# CH32V205 register map
Vendor: WCH Ltd.; File version: 1.0
Registers are 32-bit, read-write, reset 0x0 unless marked. A register's access mark holds for its fields unless they carry their own. Offsets are from the block's base; [hi:lo] are bit positions.

## QSPI1
Base 0x40024C00
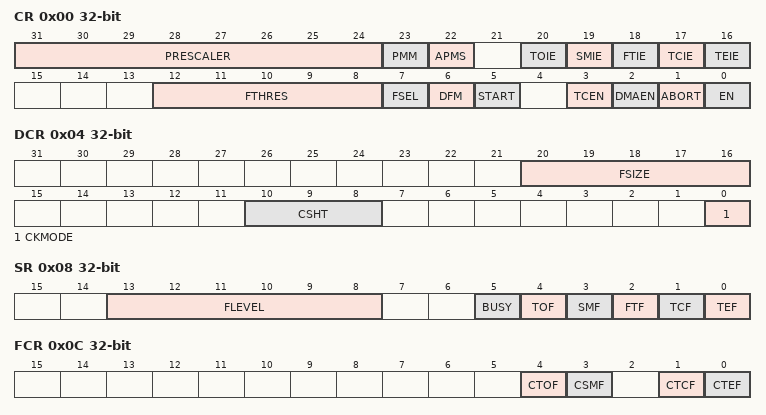
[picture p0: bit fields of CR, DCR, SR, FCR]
0x00 CR access per field — QSPI control register
  [31:24] PRESCALER rw — clock prescaler
  [23] PMM rw — Polling match mode
  [22] APMS rw — Automatic poll mode stop
  [20] TOIE rw — TimeOut interrupt enable This bit enables the TimeOut interrupt.
  [19] SMIE rw — Status match interrupt enable This bit enables the status match interrupt.
  [18] FTIE rw — FIFO threshold interrupt enable This bit enables the FIFO threshold interrupt.
  [17] TCIE rw — Transfer complete interrupt enable This bit enables the transfer complete interrupt.
  [16] TEIE rw — Transfer error interrupt enable This bit enables the transfer error interrupt.
  [12:8] FTHRES rw — FIFO threshold level Defines
  [7] FSEL rw — Flash memory selection
  [6] DFM rw — Dual-flash mode This bit activates dual-flash mode
  [5] START wo — start the FLASH command sequence
  [3] TCEN rw — Timeout counter enable
  [2] DMAEN rw — DMA mode enabled
  [1] ABORT rw — Abort request This bit aborts the on-going command sequence
  [0] EN rw — Enable Enable the QSPI
0x04 DCR — QSPI device configuration register
  [20:16] FSIZE — Flash memory size
  [10:8] CSHT — Chip select high time
  [0] CKMODE — indicates the level that clk takes between command
0x08 SR ro — QSPI status register
  [13:8] FLEVEL — FIFO level
  [5] BUSY — Busy This bit is set when an operation is on going
  [4] TOF — Timeout flag This bit is set when timeout occurs
  [3] SMF — Status match flag
  [2] FTF — FIFO threshold flag
  [1] TCF — Transfer complete flag
  [0] TEF — Transfer error flag
0x0C FCR — QSPI flag clear register
  [4] CTOF — Clear timeout flag Writing 1 clears the TOF flag in the QSPI_SR register
  [3] CSMF — Clear status match flag Writing 1 clears the SMF flag in the QSPI_SR register
  [1] CTCF — Clear transfer complete flag Writing 1 clears the TCF flag in the QSPI_SR register
  [0] CTEF — Clear transfer error flag Writing 1 clears the TEF flag in the QSPI_SR register
0x10 DLR — QSPI data length register
  [31:0] DL — Data length
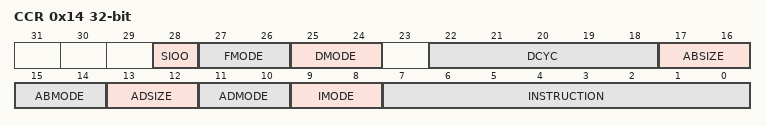
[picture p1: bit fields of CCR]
0x14 CCR — QSPI communication configuration register
  [28] SIOO — Send instruction only once mode
  [27:26] FMODE — Functional mode
  [25:24] DMODE — Data mode
  [22:18] DCYC — Number of dummy cycles
  [17:16] ABSIZE — Alternate bytes size
  [15:14] ABMODE — Alternate bytes mode
  [13:12] ADSIZE — Address size
  [11:10] ADMODE — Address mode
  [9:8] IMODE — Instruction mode
  [7:0] INSTRUCTION
0x18 AR — QSPI address register
  [31:0] ADDRESS — QSPI Address
0x1C ABR — QSPI alternate bytes registers
  [31:0] ALTERNATE — Alternate Bytes Optional data to be send to the external SPI device right after the address.
0x20 DR — QSPI data register
  [31:0] DATA
0x24 PSMKR — QSPI polling status mask register
  [31:0] MASK — Status mask Mask to be applied to the status bytes received in polling mode
0x28 PSMAR — QSPI polling status match register
  [31:0] MATCH — Status match Value to be compared with the masked status register to get a match. This field can be written only when BUSY = 0.
0x2C PIR — QSPI polling interval register
  [15:0] INTERVAL — Polling interval Number of CLK cycles between to read during automatic polling phases. This field can be written only when BUSY = 0.
0x30 LPTR — QSPI low-power timeout register
  [15:0] TIMEOUT

## FSMC — Flexible static memory controller
Base 0xA0000000
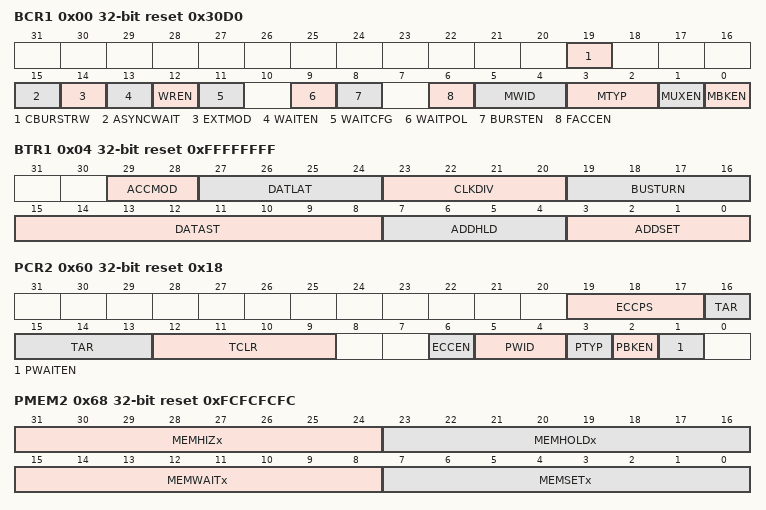
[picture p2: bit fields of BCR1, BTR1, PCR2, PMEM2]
0x00 BCR1 reset 0x30D0 — SRAM/NOR-Flash chip-select control register 1
  [19] CBURSTRW — Write burst enable
  [15] ASYNCWAIT — Wait signal during asynchronous transfers
  [14] EXTMOD — Extended mode enable
  [13] WAITEN — Wait enable bit
  [12] WREN — Write enable bit
  [11] WAITCFG — Wait timing configuration
  [9] WAITPOL — Wait signal polarity bit
  [8] BURSTEN — Burst enable bit
  [6] FACCEN — Flash access enable
  [5:4] MWID — Memory databus width
  [3:2] MTYP — Memory type
  [1] MUXEN — Address/data multiplexing enable bit
  [0] MBKEN — Memory bank enable bit
0x04 BTR1 reset 0xFFFFFFFF — SRAM/NOR-Flash chip-select timing register 1
  [29:28] ACCMOD — Access mode
  [27:24] DATLAT — Data latency for synchronous NOR Flash memory
  [23:20] CLKDIV — Clock divide ratio (for FSMC_CLK signal)
  [19:16] BUSTURN — Bus turnaround phase duration
  [15:8] DATAST — Data-phase duration
  [7:4] ADDHLD — Address-hold phase duration
  [3:0] ADDSET — Address setup phase duration
0x60 PCR2 reset 0x18 — PC Card/NAND Flash control register 2
  [19:17] ECCPS — ECC page size
  [16:13] TAR — ALE to RE delay
  [12:9] TCLR — CLE to RE delay
  [6] ECCEN — ECC computation logic enable bit
  [5:4] PWID — Databus width
  [3] PTYP — Memory type
  [2] PBKEN — PC Card/NAND Flash memory bank enable bit
  [1] PWAITEN — Wait feature enable bit
0x64 SR2 ro reset 0x40 — FIFO status and interrupt register 2
  [6] FEMPT — FIFO empty
0x68 PMEM2 reset 0xFCFCFCFC — Common memory space timing register 2
  [31:24] MEMHIZx — Common memory x databus HiZ time
  [23:16] MEMHOLDx — Common memory x hold time
  [15:8] MEMWAITx — Common memory x wait time
  [7:0] MEMSETx — Common memory x setup time
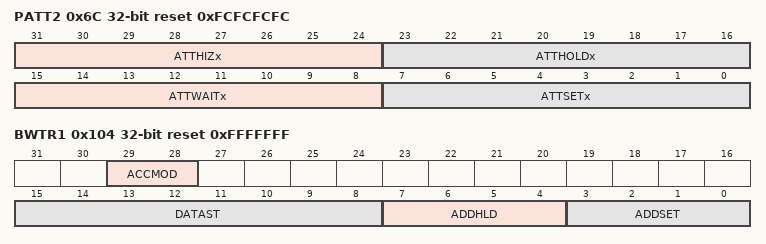
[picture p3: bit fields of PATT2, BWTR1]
0x6C PATT2 reset 0xFCFCFCFC — Attribute memory space timing register 2
  [31:24] ATTHIZx — Attribute memory x databus HiZ time
  [23:16] ATTHOLDx — Attribute memory x hold time
  [15:8] ATTWAITx — Attribute memory x wait time
  [7:0] ATTSETx — Attribute memory x setup time
0x74 ECCR2 ro — ECC result register 2
  [31:0] ECCx — ECC result
0x104 BWTR1 reset 0xFFFFFFF — SRAM/NOR-Flash write timing registers 1
  [29:28] ACCMOD — Access mode
  [15:8] DATAST — Data-phase duration
  [7:4] ADDHLD — Address-hold phase duration
  [3:0] ADDSET — Address setup phase duration

## OPA — OPA configuration
Base 0x40026000
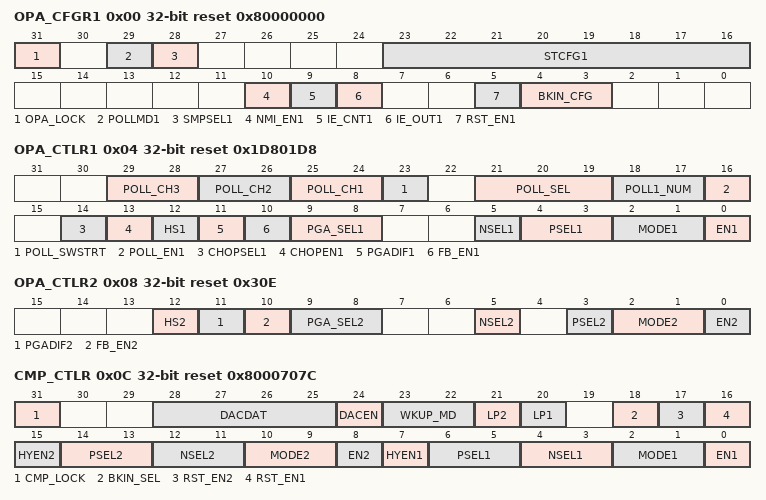
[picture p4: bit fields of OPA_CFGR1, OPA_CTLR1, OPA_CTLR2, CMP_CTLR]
0x00 OPA_CFGR1 reset 0x80000000 — OPA configuration Register 1
  [31] OPA_LOCK
  [29] POLLMD1 — OPA1 polling mode configuration register
  [28] SMPSEL1 — Sampling Source Selection Bit
  [23:16] STCFG1 — OPA1 establishes a time configuration bit in system clock cycles
  [10] NMI_EN1 — OPA connection NMI interrupt enable
  [9] IE_CNT1 — OPA interrupt enable at the end of polling interval
  [8] IE_OUT1 — OPA1 interrupt enable
  [5] RST_EN1 — OPA1 reset enable
  [4:3] BKIN_CFG — Timer brake configuration
0x04 OPA_CTLR1 access per field reset 0x1D801D8 — OPA control register 1
  [29:28] POLL_CH3 rw — OPA1 Polling Order
  [27:26] POLL_CH2 rw — OPA1 Polling Order
  [25:24] POLL_CH1 rw — OPA1 Polling Order
  [23] POLL_SWSTRT wo — To start OPA1 polling, you need to set the software trigger
  [21:19] POLL_SEL rw — OPA1 polling trigger source selection
  [18:17] POLL1_NUM rw — OPA1 polling the number of positive ends
  [16] POLL_EN1 rw — OPA1 enable positive polling
  [14] CHOPSEL1 rw — OPA1 Chopper Frequency Selection
  [13] CHOPEN1 rw — OPA1 Chopper Enablement
  [12] HS1 rw — OPA1 high-speed mode enables
  [11] PGADIF1 rw — OPA1 Output Bias Voltage Selection for Internal PGA
  [10] FB_EN1 rw — OPA1 internal feedback resistance enable
  [9:8] PGA_SEL1 rw — OPA1 Gain Selection
  [5] NSEL1 rw — OPA1 negative end channel selection with PGA gain selection
  [4:3] PSEL1 rw — OPA1 forward input selection
  [2:1] MODE1 rw — OPA1 output channel selection
  [0] EN1 rw — OPA1 enable
0x08 OPA_CTLR2 reset 0x30E — OPA control register 2
  [12] HS2 — OPA2 high-speed mode enables
  [11] PGADIF2 — OPA2 for internal PGA output bias voltage selection
  [10] FB_EN2 — OPA2 internal feedback resistance enable
  [9:8] PGA_SEL2 — OPA2 Gain Selection
  [5] NSEL2 — OPA2 negative end channel selection with PGA gain selection
  [3] PSEL2 — OPA2 forward input selection
  [2:1] MODE2 — OPA2 output channel selection
  [0] EN2 — OPA2 enable
0x0C CMP_CTLR reset 0x8000707C — CMP control register
  [31] CMP_LOCK — OPA LOCK
  [28:25] DACDAT — DAC data configuration bit
  [24] DACEN — DAC enable bit
  [23:22] WKUP_MD — CMP wake-up signal mode selection
  [21] LP2 — CMP2 low-power switch
  [20] LP1 — CMP1 low-power switch
  [18] BKIN_SEL — Timer brake source configuration
  [17] RST_EN2 — CMP2 reset enable
  [16] RST_EN1 — CMP1 reset enable
  [15] HYEN2 — CMP2 hysteresis comparator switch
  [14:13] PSEL2 — CMP2 forward input selection
  [12:11] NSEL2 — CMP2 negative input selection
  [10:9] MODE2 — CMP2 Output channel selection
  [8] EN2 — CMP2 enable
  [7] HYEN1 — CMP1 hysteresis comparator switch
  [6:5] PSEL1 — CMP1 forward input selection
  [4:3] NSEL1 — CMP1 negative input selection
  [2:1] MODE1 — CMP1 Output channel selection
  [0] EN1 — CMP1 enable
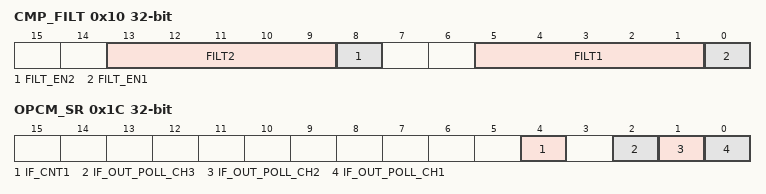
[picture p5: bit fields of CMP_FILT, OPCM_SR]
0x10 CMP_FILT — Comparator Filter Configuration Register
  [13:9] FILT2 — The CMP2 filter sampling interval configuration bit is 0.375us
  [8] FILT_EN2 — CMP2 Filter Enable Bits
  [5:1] FILT1 — The CMP1 filter sampling interval configuration bit is 0.375us
  [0] FILT_EN1 — CMP1 Filter Enable Bits
0x14 OPA_KEY — OPA unlock key Register
  [31:0] OPA_KEY — OPA unlockkey
0x18 CMP_KEY — CMP unlock key Register
  [31:0] CMP_KEY — CMP unlockkey
0x1C OPCM_SR — OPA and CMP Status Registers
  [4] IF_CNT1 — OPA1 Polling Interval End Flag
  [2] IF_OUT_POLL_CH3 — The 3rd polling channel polls to the flag that the output is high
  [1] IF_OUT_POLL_CH2 — The second polling channel polls to the flag that the output is high
  [0] IF_OUT_POLL_CH1 — The 1st polling channel polls for a flag whose output is high
